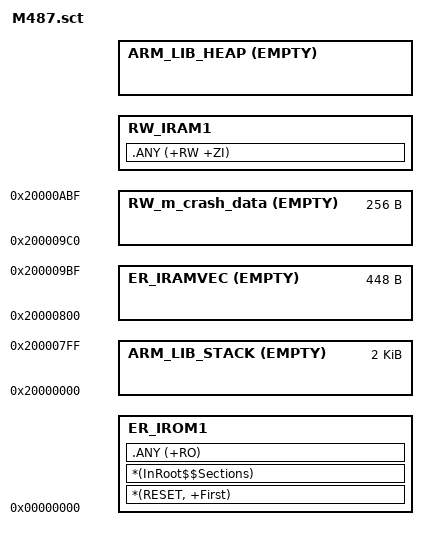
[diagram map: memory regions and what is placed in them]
#! armcc -E

#if !defined(MBED_APP_START)
  #define MBED_APP_START 0x00000000
#endif

#if !defined(MBED_APP_SIZE)
  #define MBED_APP_SIZE 0x00080000
#endif

#define SPIM_CCM_START  0x20020000
#define SPIM_CCM_END    0x20028000

#define MBED_RAM_START              0x20000000
#define MBED_RAM_SIZE               0x20000
#define MBED_STACK_RAM_START        (MBED_RAM_START)
#define MBED_STACK_RAM_SIZE         0x800
#define MBED_VECTTABLE_RAM_START    (MBED_STACK_RAM_START + MBED_STACK_RAM_SIZE)
#define MBED_VECTTABLE_RAM_SIZE     (4*(16 + 96))
#define MBED_CRASH_REPORT_RAM_START (MBED_VECTTABLE_RAM_START + MBED_VECTTABLE_RAM_SIZE)
#define MBED_CRASH_REPORT_RAM_SIZE  0x100

LR_IROM1 MBED_APP_START {
  ER_IROM1 MBED_APP_START {  ; load address = execution address
   *(RESET, +First)
   *(InRoot$$Sections)
   .ANY (+RO)
  }
  
  
  ARM_LIB_STACK MBED_STACK_RAM_START EMPTY MBED_STACK_RAM_SIZE {
  }
  
  ER_IRAMVEC MBED_VECTTABLE_RAM_START EMPTY MBED_VECTTABLE_RAM_SIZE {  ; Reserve for vectors
  }
  
  RW_m_crash_data MBED_CRASH_REPORT_RAM_START EMPTY MBED_CRASH_REPORT_RAM_SIZE { ; Reserve for crash data storage
  }
  
  RW_IRAM1 AlignExpr(+0, 16) {  ; 16 byte-aligned
   .ANY (+RW +ZI)
  }
  
  ARM_LIB_HEAP AlignExpr(+0, 16) EMPTY (0x20000000 + 0x28000 - AlignExpr(ImageLimit(RW_IRAM1), 16)) {
  }
}
ScatterAssert(LoadLimit(LR_IROM1) <= (MBED_APP_START + MBED_APP_SIZE))  ; 512 KB APROM
ScatterAssert(ImageLimit(ARM_LIB_HEAP) <= 0x20028000)   ; 160 KB SRAM
